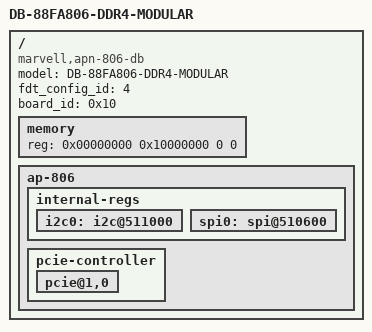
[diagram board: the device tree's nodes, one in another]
/*
 * ***************************************************************************
 * Copyright (C) 2015 Marvell International Ltd.
 * ***************************************************************************
 * This program is free software: you can redistribute it and/or modify it
 * under the terms of the GNU General Public License as published by the Free
 * Software Foundation, either version 2 of the License, or any later version.
 *
 * This program is distributed in the hope that it will be useful,
 * but WITHOUT ANY WARRANTY; without even the implied warranty of
 * MERCHANTABILITY or FITNESS FOR A PARTICULAR PURPOSE.  See the
 * GNU General Public License for more details.
 *
 * You should have received a copy of the GNU General Public License
 * along with this program.  If not, see <http://www.gnu.org/licenses/>.
 * ***************************************************************************
 */

/dts-v1/;

#include "apn-806-db.dtsi"

/ {
	model = "DB-88FA806-DDR4-MODULAR";
	compatible = "marvell,apn-806-db", "marvell,apn-806";
	fdt_config_id = <4>;
	board_id = <0x10>;

	memory {
		device_type = "memory";
		reg = <0x00000000 0x10000000 0 0>; /* 256 MB */
	};

	ap-806 {
		internal-regs {

			i2c0: i2c@511000 {
				status = "okay";
			};

			spi0: spi@510600 {
				status = "okay";
			};
		};

		pcie-controller {
			pcie@1,0 {
				status = "okay";
			};
		};
	};
};
